# DMASS_BCDMA_0_DMASS_BCDMA_0_BCDMA_CRED_45812000h register map
Vendor: Texas Instruments
Peripheral module from a debugger description file (folder am62L).
Registers are 32-bit, read-write, reset 0x0 unless marked. A register's access mark holds for its fields unless they carry their own. Offsets are as the file gives them; lines under a group give offsets from that group; [hi:lo] are bit positions; {n}, {i} and the like mark numbered series; 'fields as' and 'values as' point back to an identical list; <NAME> marks a mode.

## DMASS_BCDMA_0_BCDMA_CRED
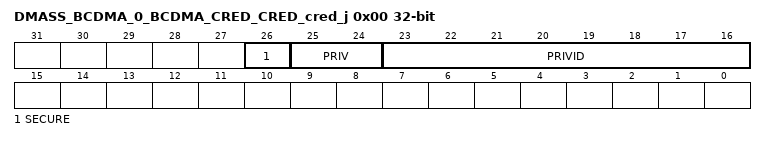
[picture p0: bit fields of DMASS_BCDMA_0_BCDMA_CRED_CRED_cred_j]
0x00 DMASS_BCDMA_0_BCDMA_CRED_CRED_cred_j — The Credentials Register provides credentials to be used when performing memory accesses using this flow.
  [26] SECURE — Secure attribute Reset Source: rst_mod_g_rst_n
  [25:24] PRIV — Privelege attribute Reset Source: rst_mod_g_rst_n
  [23:16] PRIVID — Privelege ID attribute Reset Source: rst_mod_g_rst_n
